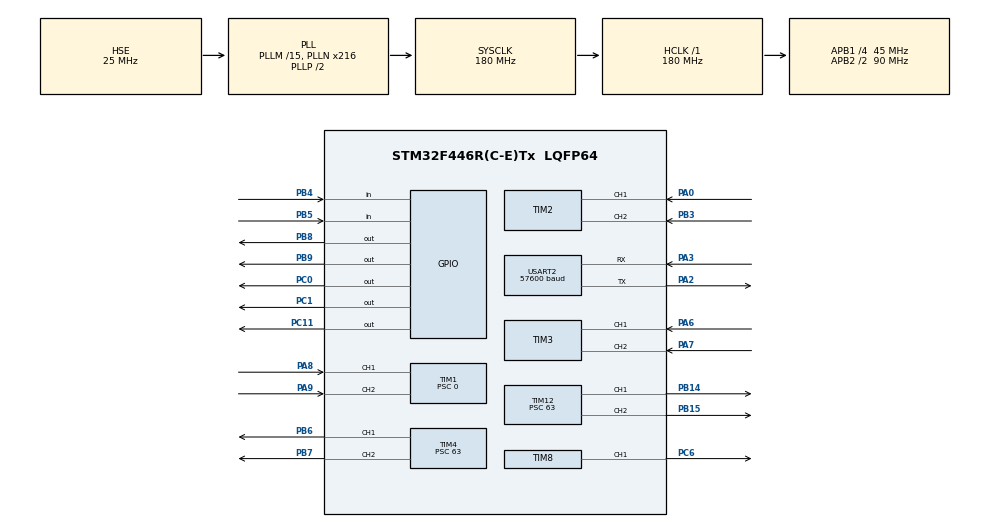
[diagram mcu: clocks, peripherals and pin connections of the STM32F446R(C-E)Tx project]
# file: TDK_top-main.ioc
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Dma.Request0=USART2_RX
Dma.Request1=USART2_TX
Dma.USART2_RX.0.Direction=DMA_PERIPH_TO_MEMORY
Dma.USART2_RX.0.FIFOMode=DMA_FIFOMODE_DISABLE
Dma.USART2_RX.0.Instance=DMA1_Stream5
Dma.USART2_RX.0.MemDataAlignment=DMA_MDATAALIGN_BYTE
Dma.USART2_RX.0.MemInc=DMA_MINC_ENABLE
Dma.USART2_RX.0.Mode=DMA_CIRCULAR
Dma.USART2_RX.0.PeriphDataAlignment=DMA_PDATAALIGN_BYTE
Dma.USART2_RX.0.PeriphInc=DMA_PINC_DISABLE
Dma.USART2_RX.0.Priority=DMA_PRIORITY_HIGH
Dma.USART2_TX.1.Direction=DMA_MEMORY_TO_PERIPH
Dma.USART2_TX.1.FIFOMode=DMA_FIFOMODE_DISABLE
Dma.USART2_TX.1.Instance=DMA1_Stream6
Dma.USART2_TX.1.MemDataAlignment=DMA_MDATAALIGN_BYTE
Dma.USART2_TX.1.MemInc=DMA_MINC_ENABLE
Dma.USART2_TX.1.Mode=DMA_NORMAL
Dma.USART2_TX.1.PeriphDataAlignment=DMA_PDATAALIGN_BYTE
Dma.USART2_TX.1.PeriphInc=DMA_PINC_DISABLE
Dma.USART2_TX.1.Priority=DMA_PRIORITY_HIGH
Mcu.Family=STM32F4
Mcu.Name=STM32F446R(C-E)Tx
Mcu.Package=LQFP64
NVIC.DMA1_Stream5_IRQn=true\:0\:0\:false\:false\:true\:false\:true\:true
NVIC.DMA1_Stream6_IRQn=true\:0\:0\:false\:false\:true\:false\:true\:true
NVIC.PriorityGroup=NVIC_PRIORITYGROUP_4
NVIC.TIM1_BRK_TIM9_IRQn=true\:0\:0\:false\:false\:true\:true\:true\:true
NVIC.TIM5_IRQn=true\:0\:0\:false\:false\:true\:true\:true\:true
NVIC.TIM8_BRK_TIM12_IRQn=true\:0\:0\:false\:false\:true\:true\:true\:true
NVIC.USART2_IRQn=true\:0\:0\:false\:false\:true\:true\:true\:true
PA0-WKUP.Signal=S_TIM2_CH1_ETR
PA2.Mode=Asynchronous
PA2.Signal=USART2_TX
PA3.Mode=Asynchronous
PA3.Signal=USART2_RX
PA6.Signal=S_TIM3_CH1
PA7.Signal=S_TIM3_CH2
PA8.Signal=S_TIM1_CH1
PA9.Signal=S_TIM1_CH2
PB14.Signal=S_TIM12_CH1
PB15.Signal=S_TIM12_CH2
PB3.Signal=S_TIM2_CH2
PB4.Signal=GPIO_Input
PB5.Signal=GPIO_Input
PB6.Signal=S_TIM4_CH1
PB7.Signal=S_TIM4_CH2
PB8.Signal=GPIO_Output
PB9.Signal=GPIO_Output
PC0.Signal=GPIO_Output
PC1.Signal=GPIO_Output
PC11.Signal=GPIO_Output
PC6.Signal=S_TIM8_CH1
PH0-OSC_IN.Mode=HSE-External-Oscillator
PH0-OSC_IN.Signal=RCC_OSC_IN
PH1-OSC_OUT.Mode=HSE-External-Oscillator
PH1-OSC_OUT.Signal=RCC_OSC_OUT
ProjectManager.HeapSize=0x200
ProjectManager.StackSize=0x400
ProjectManager.TargetToolchain=STM32CubeIDE
RCC.AHBFreq_Value=180000000
RCC.APB1CLKDivider=RCC_HCLK_DIV4
RCC.APB1Freq_Value=45000000
RCC.APB1TimFreq_Value=90000000
RCC.APB2CLKDivider=RCC_HCLK_DIV2
RCC.APB2Freq_Value=90000000
RCC.APB2TimFreq_Value=180000000
RCC.CortexFreq_Value=180000000
RCC.EnbaleCSS=true
RCC.HCLKFreq_Value=180000000
RCC.OscillatorTypeHSE-ClockTree=RCC_OSCILLATORTYPE_HSE
RCC.PLLM=15
RCC.PLLN=216
RCC.PLLSourceVirtual=RCC_PLLSOURCE_HSE
RCC.SYSCLKFreq_VALUE=180000000
RCC.SYSCLKSource=RCC_SYSCLKSOURCE_PLLCLK
RCC.USBFreq_Value=180000000
RCC.VCOOutputFreq_Value=360000000
SH.S_TIM12_CH1.0=TIM12_CH1,PWM Generation1 CH1
SH.S_TIM12_CH2.0=TIM12_CH2,PWM Generation2 CH2
SH.S_TIM1_CH1.0=TIM1_CH1,Encoder_Interface
SH.S_TIM1_CH2.0=TIM1_CH2,Encoder_Interface
SH.S_TIM2_CH1_ETR.0=TIM2_CH1,Encoder_Interface
SH.S_TIM2_CH2.0=TIM2_CH2,Encoder_Interface
SH.S_TIM3_CH1.0=TIM3_CH1,Encoder_Interface
SH.S_TIM3_CH2.0=TIM3_CH2,Encoder_Interface
SH.S_TIM4_CH1.0=TIM4_CH1,PWM Generation1 CH1
SH.S_TIM4_CH2.0=TIM4_CH2,PWM Generation2 CH2
SH.S_TIM8_CH1.0=TIM8_CH1,PWM Generation1 CH1
TIM1.Period=65535
TIM1.Prescaler=0
TIM12.Channel-PWM\ Generation1\ CH1=TIM_CHANNEL_1
TIM12.Channel-PWM\ Generation2\ CH2=TIM_CHANNEL_2
TIM12.Period=19999
TIM12.Prescaler=63
TIM12.Pulse-PWM\ Generation1\ CH1=10000
TIM12.Pulse-PWM\ Generation2\ CH2=10000
TIM4.Channel-PWM\ Generation1\ CH1=TIM_CHANNEL_1
TIM4.Channel-PWM\ Generation2\ CH2=TIM_CHANNEL_2
TIM4.Period=19999
TIM4.Prescaler=63
TIM4.Pulse-PWM\ Generation1\ CH1=600
TIM4.Pulse-PWM\ Generation2\ CH2=600
TIM5.Period=999
TIM5.Prescaler=63
TIM8.Channel-PWM\ Generation1\ CH1=TIM_CHANNEL_1
TIM8.Period=19999
TIM8.Prescaler=63
TIM8.Pulse-PWM\ Generation1\ CH1=600
USART2.BaudRate=57600
USART2.VirtualMode=VM_ASYNC
VP_TIM5_VS_ClockSourceINT.Mode=Internal
board=custom

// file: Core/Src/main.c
/* USER CODE BEGIN Header */
/**
  ******************************************************************************
  * @file           : main.c
  * @brief          : Main program body
  ******************************************************************************
  * @attention
  *
  * Copyright (c) 2023 STMicroelectronics.
  * All rights reserved.
  *
  * This software is licensed under terms that can be found in the LICENSE file
  * in the root directory of this software component.
  * If no LICENSE file comes with this software, it is provided AS-IS.
  *
  ******************************************************************************
  */
/* USER CODE END Header */
#include "main.h"

/* USER CODE BEGIN Includes */
#include "mainpp.h"
/* USER CODE END Includes */

TIM_HandleTypeDef htim1;
TIM_HandleTypeDef htim2;
TIM_HandleTypeDef htim3;
TIM_HandleTypeDef htim4;
TIM_HandleTypeDef htim5;
TIM_HandleTypeDef htim8;
TIM_HandleTypeDef htim12;

UART_HandleTypeDef huart2;
DMA_HandleTypeDef hdma_usart2_rx;
DMA_HandleTypeDef hdma_usart2_tx;

void SystemClock_Config(void);
static void MX_GPIO_Init(void);
static void MX_DMA_Init(void);
static void MX_TIM1_Init(void);
static void MX_TIM2_Init(void);
static void MX_TIM3_Init(void);
static void MX_TIM8_Init(void);
static void MX_TIM12_Init(void);
static void MX_TIM4_Init(void);
static void MX_TIM5_Init(void);
static void MX_USART2_UART_Init(void);

int main(void)
{

  /* MCU Configuration--------------------------------------------------------*/

  /* Reset of all peripherals, Initializes the Flash interface and the Systick. */
  HAL_Init();

  /* Configure the system clock */
  SystemClock_Config();

  /* Initialize all configured peripherals */
  MX_GPIO_Init();
  MX_DMA_Init();
  MX_TIM1_Init();
  MX_TIM2_Init();
  MX_TIM3_Init();
  MX_TIM8_Init();
  MX_TIM12_Init();
  MX_TIM4_Init();
  MX_TIM5_Init();
  MX_USART2_UART_Init();
  /* USER CODE BEGIN 2 */
  main_function();
  //PWM
  HAL_TIM_PWM_Start(&htim4,TIM_CHANNEL_1);	//PB6 -> attach servo
  HAL_TIM_PWM_Start(&htim4,TIM_CHANNEL_2);	//PB7 -> ball_seat servo

  HAL_TIM_PWM_Start(&htim12,TIM_CHANNEL_1);	//PB14 -> horizontal_angle speed
  HAL_TIM_PWM_Start(&htim12,TIM_CHANNEL_2);	//PB15 -> elevation_angle speed

//  //Encoder
  HAL_TIM_Encoder_Start(&htim1,TIM_CHANNEL_1);	//Shooter Encoder tl1
  HAL_TIM_Encoder_Start(&htim1,TIM_CHANNEL_2);	//Shooter Encoder tl2
  HAL_TIM_Encoder_Start(&htim2,TIM_CHANNEL_1);	//horizontal_angle Encoder tl1
  HAL_TIM_Encoder_Start(&htim2,TIM_CHANNEL_2);	//horizontal_angle Encoder tl2
  HAL_TIM_Encoder_Start(&htim3,TIM_CHANNEL_1);	//elevation_angle Encoder tl1
  HAL_TIM_Encoder_Start(&htim3,TIM_CHANNEL_2);	//elevation_angle Encoder tl2
//  //Timer Interupt
  HAL_TIM_Base_Start_IT(&htim8); //PSC 63 , ARR 999 -> 1kHz

  //main function

  /* USER CODE END 2 */

  /* Infinite loop */
  while (1)
  {

  }
}

void SystemClock_Config(void)
{
  RCC_OscInitTypeDef RCC_OscInitStruct = {0};
  RCC_ClkInitTypeDef RCC_ClkInitStruct = {0};

  /** Configure the main internal regulator output voltage
  */
  __HAL_RCC_PWR_CLK_ENABLE();
  __HAL_PWR_VOLTAGESCALING_CONFIG(PWR_REGULATOR_VOLTAGE_SCALE1);

  /** Initializes the RCC Oscillators according to the specified parameters
  * in the RCC_OscInitTypeDef structure.
  */
  RCC_OscInitStruct.OscillatorType = RCC_OSCILLATORTYPE_HSE;
  RCC_OscInitStruct.PLL.PLLState = RCC_PLL_ON;
  RCC_OscInitStruct.PLL.PLLSource = RCC_PLLSOURCE_HSE;
  RCC_OscInitStruct.PLL.PLLM = 15;
  RCC_OscInitStruct.PLL.PLLN = 216;
  RCC_OscInitStruct.PLL.PLLP = RCC_PLLP_DIV2;
  RCC_OscInitStruct.PLL.PLLQ = 2;
  RCC_OscInitStruct.PLL.PLLR = 2;
  if (HAL_RCC_OscConfig(&RCC_OscInitStruct) != HAL_OK)
  {
    Error_Handler();
  }

  /** Activate the Over-Drive mode
  */
  if (HAL_PWREx_EnableOverDrive() != HAL_OK)
  {
    Error_Handler();
  }

  /** Initializes the CPU, AHB and APB buses clocks
  */
  RCC_ClkInitStruct.ClockType = RCC_CLOCKTYPE_HCLK|RCC_CLOCKTYPE_SYSCLK
                              |RCC_CLOCKTYPE_PCLK1|RCC_CLOCKTYPE_PCLK2;
  RCC_ClkInitStruct.SYSCLKSource = RCC_SYSCLKSOURCE_PLLCLK;
  RCC_ClkInitStruct.AHBCLKDivider = RCC_SYSCLK_DIV1;
  RCC_ClkInitStruct.APB1CLKDivider = RCC_HCLK_DIV4;
  RCC_ClkInitStruct.APB2CLKDivider = RCC_HCLK_DIV2;

  if (HAL_RCC_ClockConfig(&RCC_ClkInitStruct, FLASH_LATENCY_5) != HAL_OK)
  {
    Error_Handler();
  }

  /** Enables the Clock Security System
  */
  HAL_RCC_EnableCSS();
}

static void MX_TIM1_Init(void)
{

  TIM_Encoder_InitTypeDef sConfig = {0};
  TIM_MasterConfigTypeDef sMasterConfig = {0};

  htim1.Instance = TIM1;
  htim1.Init.Prescaler = 0;
  htim1.Init.CounterMode = TIM_COUNTERMODE_UP;
  htim1.Init.Period = 65535;
  htim1.Init.ClockDivision = TIM_CLOCKDIVISION_DIV1;
  htim1.Init.RepetitionCounter = 0;
  htim1.Init.AutoReloadPreload = TIM_AUTORELOAD_PRELOAD_DISABLE;
  sConfig.EncoderMode = TIM_ENCODERMODE_TI1;
  sConfig.IC1Polarity = TIM_ICPOLARITY_RISING;
  sConfig.IC1Selection = TIM_ICSELECTION_DIRECTTI;
  sConfig.IC1Prescaler = TIM_ICPSC_DIV1;
  sConfig.IC1Filter = 0;
  sConfig.IC2Polarity = TIM_ICPOLARITY_RISING;
  sConfig.IC2Selection = TIM_ICSELECTION_DIRECTTI;
  sConfig.IC2Prescaler = TIM_ICPSC_DIV1;
  sConfig.IC2Filter = 0;
  if (HAL_TIM_Encoder_Init(&htim1, &sConfig) != HAL_OK)
  {
    Error_Handler();
  }
  sMasterConfig.MasterOutputTrigger = TIM_TRGO_RESET;
  sMasterConfig.MasterSlaveMode = TIM_MASTERSLAVEMODE_DISABLE;
  if (HAL_TIMEx_MasterConfigSynchronization(&htim1, &sMasterConfig) != HAL_OK)
  {
    Error_Handler();
  }

}

static void MX_TIM2_Init(void)
{

  TIM_Encoder_InitTypeDef sConfig = {0};
  TIM_MasterConfigTypeDef sMasterConfig = {0};

  htim2.Instance = TIM2;
  htim2.Init.Prescaler = 0;
  htim2.Init.CounterMode = TIM_COUNTERMODE_UP;
  htim2.Init.Period = 4294967295;
  htim2.Init.ClockDivision = TIM_CLOCKDIVISION_DIV1;
  htim2.Init.AutoReloadPreload = TIM_AUTORELOAD_PRELOAD_DISABLE;
  sConfig.EncoderMode = TIM_ENCODERMODE_TI1;
  sConfig.IC1Polarity = TIM_ICPOLARITY_RISING;
  sConfig.IC1Selection = TIM_ICSELECTION_DIRECTTI;
  sConfig.IC1Prescaler = TIM_ICPSC_DIV1;
  sConfig.IC1Filter = 0;
  sConfig.IC2Polarity = TIM_ICPOLARITY_RISING;
  sConfig.IC2Selection = TIM_ICSELECTION_DIRECTTI;
  sConfig.IC2Prescaler = TIM_ICPSC_DIV1;
  sConfig.IC2Filter = 0;
  if (HAL_TIM_Encoder_Init(&htim2, &sConfig) != HAL_OK)
  {
    Error_Handler();
  }
  sMasterConfig.MasterOutputTrigger = TIM_TRGO_RESET;
  sMasterConfig.MasterSlaveMode = TIM_MASTERSLAVEMODE_DISABLE;
  if (HAL_TIMEx_MasterConfigSynchronization(&htim2, &sMasterConfig) != HAL_OK)
  {
    Error_Handler();
  }

}

static void MX_TIM3_Init(void)
{

  TIM_Encoder_InitTypeDef sConfig = {0};
  TIM_MasterConfigTypeDef sMasterConfig = {0};

  htim3.Instance = TIM3;
  htim3.Init.Prescaler = 0;
  htim3.Init.CounterMode = TIM_COUNTERMODE_UP;
  htim3.Init.Period = 65535;
  htim3.Init.ClockDivision = TIM_CLOCKDIVISION_DIV1;
  htim3.Init.AutoReloadPreload = TIM_AUTORELOAD_PRELOAD_DISABLE;
  sConfig.EncoderMode = TIM_ENCODERMODE_TI1;
  sConfig.IC1Polarity = TIM_ICPOLARITY_RISING;
  sConfig.IC1Selection = TIM_ICSELECTION_DIRECTTI;
  sConfig.IC1Prescaler = TIM_ICPSC_DIV1;
  sConfig.IC1Filter = 0;
  sConfig.IC2Polarity = TIM_ICPOLARITY_RISING;
  sConfig.IC2Selection = TIM_ICSELECTION_DIRECTTI;
  sConfig.IC2Prescaler = TIM_ICPSC_DIV1;
  sConfig.IC2Filter = 0;
  if (HAL_TIM_Encoder_Init(&htim3, &sConfig) != HAL_OK)
  {
    Error_Handler();
  }
  sMasterConfig.MasterOutputTrigger = TIM_TRGO_RESET;
  sMasterConfig.MasterSlaveMode = TIM_MASTERSLAVEMODE_DISABLE;
  if (HAL_TIMEx_MasterConfigSynchronization(&htim3, &sMasterConfig) != HAL_OK)
  {
    Error_Handler();
  }

}

static void MX_TIM4_Init(void)
{

  TIM_MasterConfigTypeDef sMasterConfig = {0};
  TIM_OC_InitTypeDef sConfigOC = {0};

  htim4.Instance = TIM4;
  htim4.Init.Prescaler = 63;
  htim4.Init.CounterMode = TIM_COUNTERMODE_UP;
  htim4.Init.Period = 19999;
  htim4.Init.ClockDivision = TIM_CLOCKDIVISION_DIV1;
  htim4.Init.AutoReloadPreload = TIM_AUTORELOAD_PRELOAD_DISABLE;
  if (HAL_TIM_PWM_Init(&htim4) != HAL_OK)
  {
    Error_Handler();
  }
  sMasterConfig.MasterOutputTrigger = TIM_TRGO_RESET;
  sMasterConfig.MasterSlaveMode = TIM_MASTERSLAVEMODE_DISABLE;
  if (HAL_TIMEx_MasterConfigSynchronization(&htim4, &sMasterConfig) != HAL_OK)
  {
    Error_Handler();
  }
  sConfigOC.OCMode = TIM_OCMODE_PWM1;
  sConfigOC.Pulse = 600;
  sConfigOC.OCPolarity = TIM_OCPOLARITY_HIGH;
  sConfigOC.OCFastMode = TIM_OCFAST_DISABLE;
  if (HAL_TIM_PWM_ConfigChannel(&htim4, &sConfigOC, TIM_CHANNEL_1) != HAL_OK)
  {
    Error_Handler();
  }
  if (HAL_TIM_PWM_ConfigChannel(&htim4, &sConfigOC, TIM_CHANNEL_2) != HAL_OK)
  {
    Error_Handler();
  }
  HAL_TIM_MspPostInit(&htim4);

}

static void MX_TIM5_Init(void)
{

  TIM_ClockConfigTypeDef sClockSourceConfig = {0};
  TIM_MasterConfigTypeDef sMasterConfig = {0};

  htim5.Instance = TIM5;
  htim5.Init.Prescaler = 63;
  htim5.Init.CounterMode = TIM_COUNTERMODE_UP;
  htim5.Init.Period = 999;
  htim5.Init.ClockDivision = TIM_CLOCKDIVISION_DIV1;
  htim5.Init.AutoReloadPreload = TIM_AUTORELOAD_PRELOAD_DISABLE;
  if (HAL_TIM_Base_Init(&htim5) != HAL_OK)
  {
    Error_Handler();
  }
  sClockSourceConfig.ClockSource = TIM_CLOCKSOURCE_INTERNAL;
  if (HAL_TIM_ConfigClockSource(&htim5, &sClockSourceConfig) != HAL_OK)
  {
    Error_Handler();
  }
  sMasterConfig.MasterOutputTrigger = TIM_TRGO_RESET;
  sMasterConfig.MasterSlaveMode = TIM_MASTERSLAVEMODE_DISABLE;
  if (HAL_TIMEx_MasterConfigSynchronization(&htim5, &sMasterConfig) != HAL_OK)
  {
    Error_Handler();
  }

}

static void MX_TIM8_Init(void)
{

  TIM_MasterConfigTypeDef sMasterConfig = {0};
  TIM_OC_InitTypeDef sConfigOC = {0};
  TIM_BreakDeadTimeConfigTypeDef sBreakDeadTimeConfig = {0};

  htim8.Instance = TIM8;
  htim8.Init.Prescaler = 63;
  htim8.Init.CounterMode = TIM_COUNTERMODE_UP;
  htim8.Init.Period = 19999;
  htim8.Init.ClockDivision = TIM_CLOCKDIVISION_DIV1;
  htim8.Init.RepetitionCounter = 0;
  htim8.Init.AutoReloadPreload = TIM_AUTORELOAD_PRELOAD_DISABLE;
  if (HAL_TIM_PWM_Init(&htim8) != HAL_OK)
  {
    Error_Handler();
  }
  sMasterConfig.MasterOutputTrigger = TIM_TRGO_RESET;
  sMasterConfig.MasterSlaveMode = TIM_MASTERSLAVEMODE_DISABLE;
  if (HAL_TIMEx_MasterConfigSynchronization(&htim8, &sMasterConfig) != HAL_OK)
  {
    Error_Handler();
  }
  sConfigOC.OCMode = TIM_OCMODE_PWM1;
  sConfigOC.Pulse = 600;
  sConfigOC.OCPolarity = TIM_OCPOLARITY_HIGH;
  sConfigOC.OCNPolarity = TIM_OCNPOLARITY_HIGH;
  sConfigOC.OCFastMode = TIM_OCFAST_DISABLE;
  sConfigOC.OCIdleState = TIM_OCIDLESTATE_RESET;
  sConfigOC.OCNIdleState = TIM_OCNIDLESTATE_RESET;
  if (HAL_TIM_PWM_ConfigChannel(&htim8, &sConfigOC, TIM_CHANNEL_1) != HAL_OK)
  {
    Error_Handler();
  }
  sBreakDeadTimeConfig.OffStateRunMode = TIM_OSSR_DISABLE;
  sBreakDeadTimeConfig.OffStateIDLEMode = TIM_OSSI_DISABLE;
  sBreakDeadTimeConfig.LockLevel = TIM_LOCKLEVEL_OFF;
  sBreakDeadTimeConfig.DeadTime = 0;
  sBreakDeadTimeConfig.BreakState = TIM_BREAK_DISABLE;
  sBreakDeadTimeConfig.BreakPolarity = TIM_BREAKPOLARITY_HIGH;
  sBreakDeadTimeConfig.AutomaticOutput = TIM_AUTOMATICOUTPUT_DISABLE;
  if (HAL_TIMEx_ConfigBreakDeadTime(&htim8, &sBreakDeadTimeConfig) != HAL_OK)
  {
    Error_Handler();
  }
  HAL_TIM_MspPostInit(&htim8);

}

static void MX_TIM12_Init(void)
{

  TIM_OC_InitTypeDef sConfigOC = {0};

  htim12.Instance = TIM12;
  htim12.Init.Prescaler = 63;
  htim12.Init.CounterMode = TIM_COUNTERMODE_UP;
  htim12.Init.Period = 19999;
  htim12.Init.ClockDivision = TIM_CLOCKDIVISION_DIV1;
  htim12.Init.AutoReloadPreload = TIM_AUTORELOAD_PRELOAD_DISABLE;
  if (HAL_TIM_PWM_Init(&htim12) != HAL_OK)
  {
    Error_Handler();
  }
  sConfigOC.OCMode = TIM_OCMODE_PWM1;
  sConfigOC.Pulse = 10000;
  sConfigOC.OCPolarity = TIM_OCPOLARITY_HIGH;
  sConfigOC.OCFastMode = TIM_OCFAST_DISABLE;
  if (HAL_TIM_PWM_ConfigChannel(&htim12, &sConfigOC, TIM_CHANNEL_1) != HAL_OK)
  {
    Error_Handler();
  }
  if (HAL_TIM_PWM_ConfigChannel(&htim12, &sConfigOC, TIM_CHANNEL_2) != HAL_OK)
  {
    Error_Handler();
  }
  HAL_TIM_MspPostInit(&htim12);

}

static void MX_USART2_UART_Init(void)
{

  huart2.Instance = USART2;
  huart2.Init.BaudRate = 57600;
  huart2.Init.WordLength = UART_WORDLENGTH_8B;
  huart2.Init.StopBits = UART_STOPBITS_1;
  huart2.Init.Parity = UART_PARITY_NONE;
  huart2.Init.Mode = UART_MODE_TX_RX;
  huart2.Init.HwFlowCtl = UART_HWCONTROL_NONE;
  huart2.Init.OverSampling = UART_OVERSAMPLING_16;
  if (HAL_UART_Init(&huart2) != HAL_OK)
  {
    Error_Handler();
  }

}

static void MX_DMA_Init(void)
{

  /* DMA controller clock enable */
  __HAL_RCC_DMA1_CLK_ENABLE();

  /* DMA interrupt init */
  /* DMA1_Stream5_IRQn interrupt configuration */
  HAL_NVIC_SetPriority(DMA1_Stream5_IRQn, 0, 0);
  HAL_NVIC_EnableIRQ(DMA1_Stream5_IRQn);
  /* DMA1_Stream6_IRQn interrupt configuration */
  HAL_NVIC_SetPriority(DMA1_Stream6_IRQn, 0, 0);
  HAL_NVIC_EnableIRQ(DMA1_Stream6_IRQn);

}

static void MX_GPIO_Init(void)
{
  GPIO_InitTypeDef GPIO_InitStruct = {0};

  /* GPIO Ports Clock Enable */
  __HAL_RCC_GPIOH_CLK_ENABLE();
  __HAL_RCC_GPIOC_CLK_ENABLE();
  __HAL_RCC_GPIOA_CLK_ENABLE();
  __HAL_RCC_GPIOB_CLK_ENABLE();

  /*Configure GPIO pin Output Level */
  HAL_GPIO_WritePin(GPIOC, GPIO_PIN_0|GPIO_PIN_1|GPIO_PIN_11, GPIO_PIN_RESET);

  /*Configure GPIO pin Output Level */
  HAL_GPIO_WritePin(GPIOB, GPIO_PIN_8|GPIO_PIN_9, GPIO_PIN_RESET);

  /*Configure GPIO pins : PC0 PC1 PC11 */
  GPIO_InitStruct.Pin = GPIO_PIN_0|GPIO_PIN_1|GPIO_PIN_11;
  GPIO_InitStruct.Mode = GPIO_MODE_OUTPUT_PP;
  GPIO_InitStruct.Pull = GPIO_NOPULL;
  GPIO_InitStruct.Speed = GPIO_SPEED_FREQ_LOW;
  HAL_GPIO_Init(GPIOC, &GPIO_InitStruct);

  /*Configure GPIO pins : PB4 PB5 */
  GPIO_InitStruct.Pin = GPIO_PIN_4|GPIO_PIN_5;
  GPIO_InitStruct.Mode = GPIO_MODE_INPUT;
  GPIO_InitStruct.Pull = GPIO_NOPULL;
  HAL_GPIO_Init(GPIOB, &GPIO_InitStruct);

  /*Configure GPIO pins : PB8 PB9 */
  GPIO_InitStruct.Pin = GPIO_PIN_8|GPIO_PIN_9;
  GPIO_InitStruct.Mode = GPIO_MODE_OUTPUT_PP;
  GPIO_InitStruct.Pull = GPIO_NOPULL;
  GPIO_InitStruct.Speed = GPIO_SPEED_FREQ_LOW;
  HAL_GPIO_Init(GPIOB, &GPIO_InitStruct);

}

void Error_Handler(void)
{
  __disable_irq();
  while (1)
  {
  }
}
